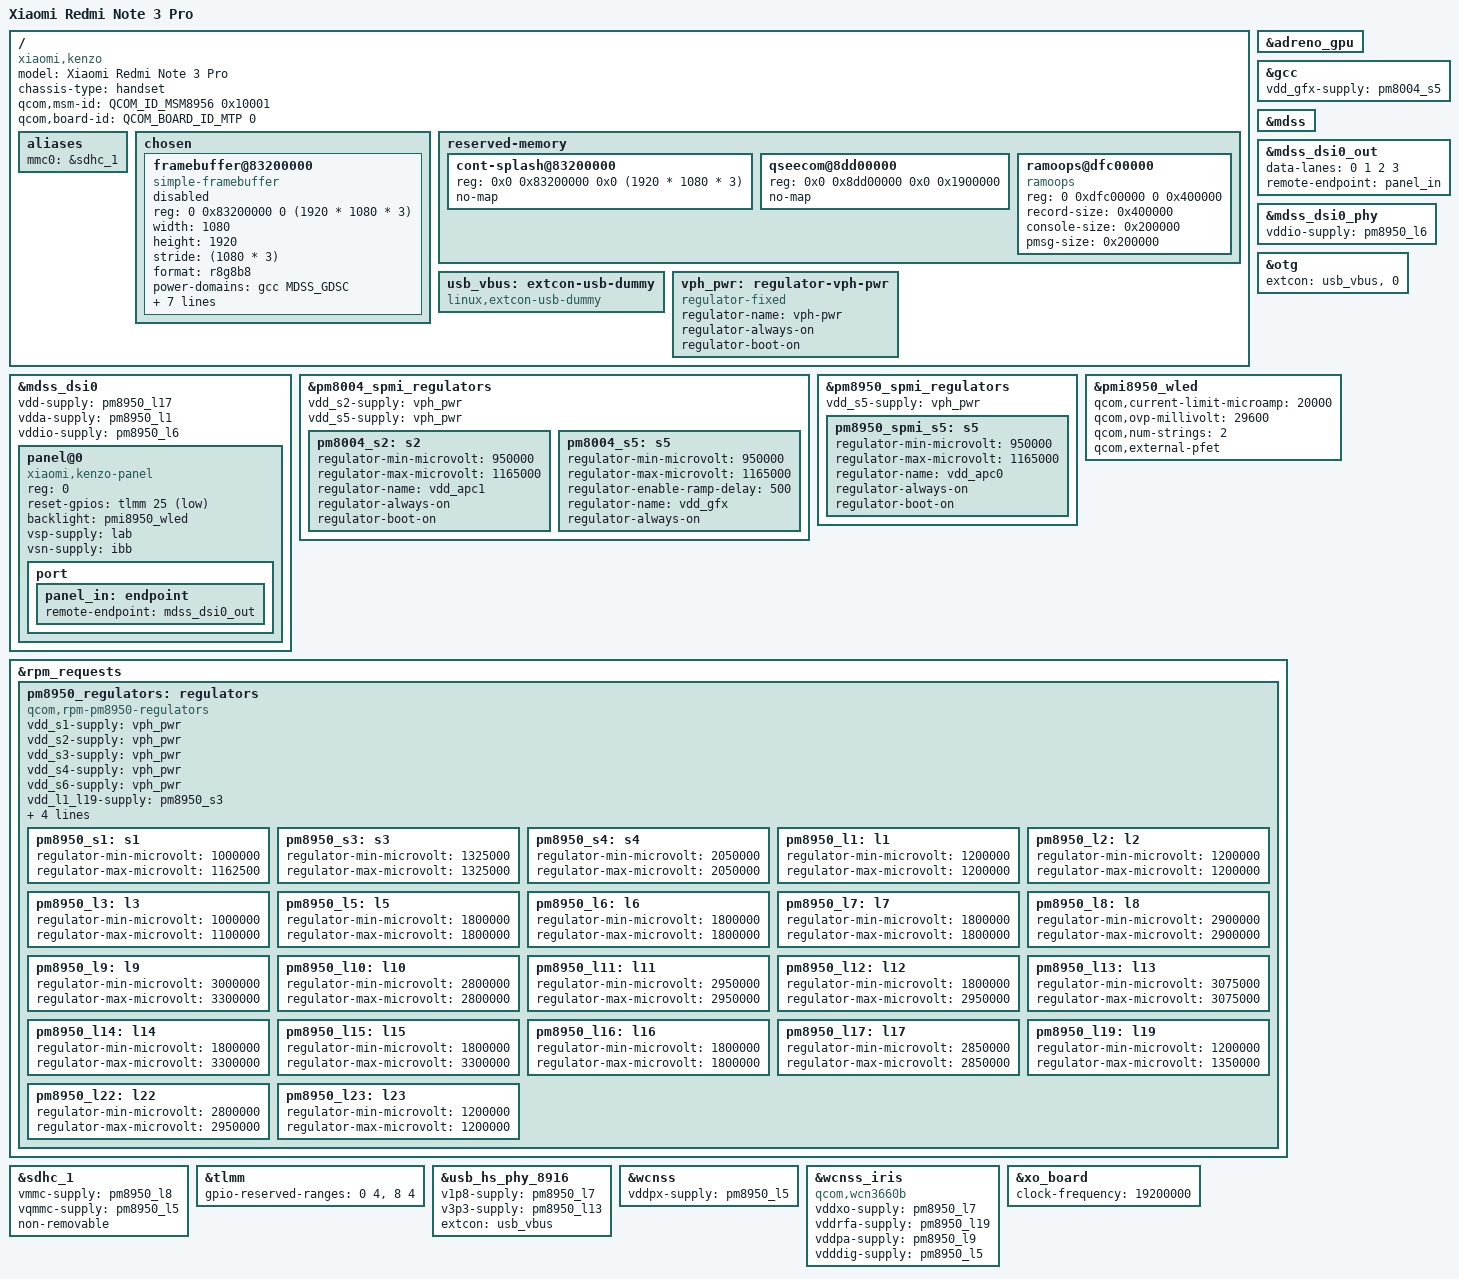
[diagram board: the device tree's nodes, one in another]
// SPDX-License-Identifier: BSD-3-Clause
/*
 * Copyright (c) 2024, Barnabas Czeman <trabarni@gmail.com>
 */
/dts-v1/;

#include <dt-bindings/arm/qcom,ids.h>

#include "msm8956.dtsi"

#include "pm8004.dtsi"
#include "pm8950.dtsi"
#include "pmi8950.dtsi"

/ {
	model = "Xiaomi Redmi Note 3 Pro";
	compatible = "xiaomi,kenzo", "qcom,msm8956";
	chassis-type = "handset";
	qcom,msm-id = <QCOM_ID_MSM8956 0x10001>;
	qcom,board-id = <QCOM_BOARD_ID_MTP 0>;

	aliases {
		mmc0 = &sdhc_1;
		// mmc1 = &sdhc_2;
	};

	chosen {
		#address-cells = <2>;
		#size-cells = <2>;
		ranges;

		framebuffer@83200000 {
			compatible = "simple-framebuffer";
			reg = <0 0x83200000 0 (1920 * 1080 * 3)>;

			width = <1080>;
			height = <1920>;
			stride = <(1080 * 3)>;
			format = "r8g8b8";

			power-domains = <&gcc MDSS_GDSC>;

			clocks = <&gcc GCC_MDSS_AHB_CLK>,
				 <&gcc GCC_MDSS_AXI_CLK>,
				 <&gcc GCC_MDSS_VSYNC_CLK>,
				 <&gcc GCC_MDSS_MDP_CLK>,
				 <&gcc GCC_MDSS_BYTE0_CLK>,
				 <&gcc GCC_MDSS_PCLK0_CLK>,
				 <&gcc GCC_MDSS_ESC0_CLK>;

			status = "disabled";
		};
	};

	reserved-memory {
		cont-splash@83200000 {
			reg = <0x0 0x83200000 0x0 (1920 * 1080 * 3)>;
			no-map;
		};

		/delete-node/ ext-region@85b00000;
		/delete-node/ tz-apps@8dd00000;
		qseecom@8dd00000 {
			reg = <0x0 0x8dd00000 0x0 0x1900000>;
			no-map;
		};

		ramoops@dfc00000 {
			compatible = "ramoops";
			reg = <0 0xdfc00000 0 0x400000>;
			record-size = <0x400000>;
			console-size = <0x200000>;
			pmsg-size = <0x200000>;
		};
	};

	/*usb_id: usb-id {
		compatible = "linux,extcon-usb-gpio";
		id-gpios = <&tlmm 17 GPIO_ACTIVE_HIGH>;
		// pinctrl-0 = <&usb_id_default>;
		// pinctrl-names = "default";
	};*/

	usb_vbus: extcon-usb-dummy {
		compatible = "linux,extcon-usb-dummy";
	};

	vph_pwr: regulator-vph-pwr {
		compatible = "regulator-fixed";
		regulator-name = "vph-pwr";
		regulator-always-on;
		regulator-boot-on;
	};
};

&adreno_gpu {
	status = "okay";
};

&gcc {
	vdd_gfx-supply = <&pm8004_s5>;
};

&mdss {
	status = "okay";
};

&mdss_dsi0 {
	vdd-supply = <&pm8950_l17>;
	vdda-supply = <&pm8950_l1>;
	vddio-supply = <&pm8950_l6>;

	status = "okay";

	panel@0 {
		compatible = "xiaomi,kenzo-panel";
		reg = <0>;

		reset-gpios = <&tlmm 25 GPIO_ACTIVE_LOW>;
		backlight = <&pmi8950_wled>;

		vsp-supply = <&lab>;
		vsn-supply = <&ibb>;

		port {
			panel_in: endpoint {
				remote-endpoint = <&mdss_dsi0_out>;
			};
		};
	};
};

&mdss_dsi0_out {
	data-lanes = <0 1 2 3>;
	remote-endpoint = <&panel_in>;
};

&mdss_dsi0_phy {
	vddio-supply = <&pm8950_l6>;
	status = "okay";
};

&otg {
	extcon = <&usb_vbus>, <0>;
	status = "okay";
};

&pm8004_spmi_regulators {
	vdd_s2-supply = <&vph_pwr>;
	vdd_s5-supply = <&vph_pwr>;

	/* Cluster 1 supply */
	pm8004_s2: s2 {
		/* regulator-min-microvolt = <500000>; */
		/* Set .95V to prevent unstabilities until CPR for this SoC is done */
		regulator-min-microvolt = <950000>;
		regulator-max-microvolt = <1165000>;
		regulator-name = "vdd_apc1";
		/* Set always on until the CPU PLL is done */
		regulator-always-on;
		regulator-boot-on;
	};

	pm8004_s5: s5 {
		regulator-min-microvolt = <950000>;
		regulator-max-microvolt = <1165000>;
		regulator-enable-ramp-delay = <500>;
		regulator-name = "vdd_gfx";
		/* Hack this on until the gpu driver is ready for it */
		regulator-always-on;
	};
};

&pm8950_spmi_regulators {
	vdd_s5-supply = <&vph_pwr>;

	/* Cluster 0 supply */
	pm8950_spmi_s5: s5 {
		/* Set .95V to prevent unstabilities until CPR for this SoC is done */
		/* regulator-min-microvolt = <500000>; */
		regulator-min-microvolt = <950000>;
		regulator-max-microvolt = <1165000>;
		regulator-name = "vdd_apc0";
		/* Set always on until the CPU PLL is done */
		regulator-always-on;
		regulator-boot-on;
	};
};

&pmi8950_wled {
	qcom,current-limit-microamp = <20000>;
	qcom,ovp-millivolt = <29600>;
	qcom,num-strings = <2>;
	qcom,external-pfet;

	status = "okay";
};

&rpm_requests {
	pm8950_regulators: regulators {
		compatible = "qcom,rpm-pm8950-regulators";

		vdd_s1-supply = <&vph_pwr>;
		vdd_s2-supply = <&vph_pwr>;
		vdd_s3-supply = <&vph_pwr>;
		vdd_s4-supply = <&vph_pwr>;
		vdd_s6-supply = <&vph_pwr>;
		vdd_l1_l19-supply = <&pm8950_s3>;
		vdd_l2_l23-supply = <&pm8950_s3>;
		vdd_l3-supply = <&pm8950_s3>;
		vdd_l5_l6_l7_l16-supply = <&pm8950_s4>;
		vdd_l8_l11_l12_l17_l22-supply = <&vph_pwr>;

		pm8950_s1: s1 {
			regulator-min-microvolt = <1000000>;
			regulator-max-microvolt = <1162500>;
		};

		pm8950_s3: s3 {
			regulator-min-microvolt = <1325000>;
			regulator-max-microvolt = <1325000>;
		};

		pm8950_s4: s4 {
			regulator-min-microvolt = <2050000>;
			regulator-max-microvolt = <2050000>;
		};

		pm8950_l1: l1 {
			regulator-min-microvolt = <1200000>;
			regulator-max-microvolt = <1200000>;
		};

		pm8950_l2: l2 {
			regulator-min-microvolt = <1200000>;
			regulator-max-microvolt = <1200000>;
		};

		pm8950_l3: l3 {
			regulator-min-microvolt = <1000000>;
			regulator-max-microvolt = <1100000>;
		};

		pm8950_l5: l5 {
			regulator-min-microvolt = <1800000>;
			regulator-max-microvolt = <1800000>;
		};

		pm8950_l6: l6 {
			regulator-min-microvolt = <1800000>;
			regulator-max-microvolt = <1800000>;
		};

		pm8950_l7: l7 {
			regulator-min-microvolt = <1800000>;
			regulator-max-microvolt = <1800000>;
		};

		pm8950_l8: l8 {
			regulator-min-microvolt = <2900000>;
			regulator-max-microvolt = <2900000>;
		};

		pm8950_l9: l9 {
			regulator-min-microvolt = <3000000>;
			regulator-max-microvolt = <3300000>;
		};

		pm8950_l10: l10 {
			regulator-min-microvolt = <2800000>;
			regulator-max-microvolt = <2800000>;
		};

		pm8950_l11: l11 {
			regulator-min-microvolt = <2950000>;
			regulator-max-microvolt = <2950000>;
		};

		pm8950_l12: l12 {
			regulator-min-microvolt = <1800000>;
			regulator-max-microvolt = <2950000>;
		};

		pm8950_l13: l13 {
			regulator-min-microvolt = <3075000>;
			regulator-max-microvolt = <3075000>;
		};

		pm8950_l14: l14 {
			regulator-min-microvolt = <1800000>;
			regulator-max-microvolt = <3300000>;
		};

		pm8950_l15: l15 {
			regulator-min-microvolt = <1800000>;
			regulator-max-microvolt = <3300000>;
		};

		pm8950_l16: l16 {
			regulator-min-microvolt = <1800000>;
			regulator-max-microvolt = <1800000>;
		};

		pm8950_l17: l17 {
			regulator-min-microvolt = <2850000>;
			regulator-max-microvolt = <2850000>;
		};

		pm8950_l19: l19 {
			regulator-min-microvolt = <1200000>;
			regulator-max-microvolt = <1350000>;
		};

		pm8950_l22: l22 {
			regulator-min-microvolt = <2800000>;
			regulator-max-microvolt = <2950000>;
		};

		pm8950_l23: l23 {
			regulator-min-microvolt = <1200000>;
			regulator-max-microvolt = <1200000>;
		};
	};
};


&sdhc_1 {
	vmmc-supply = <&pm8950_l8>;
	vqmmc-supply = <&pm8950_l5>;
	non-removable;

	status = "okay";
};
/*
&sdhc_2 {
	bus-width = <4>;
	cd-gpios = <&tlmm 100 GPIO_ACTIVE_HIGH>;
	vmmc-supply = <&pm8950_l11>;
	vqmmc-supply = <&pm8950_l12>;
	status = "okay";
};*/

&tlmm {
	gpio-reserved-ranges = <0 4>, <8 4>;
};

&usb_hs_phy_8916 {
	v1p8-supply = <&pm8950_l7>;
	v3p3-supply = <&pm8950_l13>;
	extcon = <&usb_vbus>;
	status = "okay";
};


&wcnss {
	vddpx-supply = <&pm8950_l5>;
	status = "okay";
};

&wcnss_iris {
	compatible = "qcom,wcn3660b";
	vddxo-supply = <&pm8950_l7>;
	vddrfa-supply = <&pm8950_l19>;
	vddpa-supply = <&pm8950_l9>;
	vdddig-supply = <&pm8950_l5>;
	status = "okay";
};

&xo_board {
	clock-frequency = <19200000>;
};
